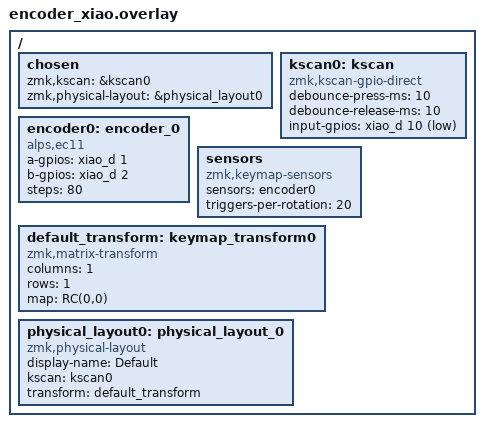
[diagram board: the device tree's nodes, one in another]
#include <dt-bindings/zmk/matrix_transform.h>

/ {
    chosen {
        zmk,kscan = &kscan0;
        zmk,physical-layout = &physical_layout0;
    };

    /*
     * main-board PH 3-pin (B3B-PH) <-> encoder-board:
     *   A = XIAO D1
     *   B = XIAO D2
     *   C = GND
     *
     * ZMK still expects a kscan node; D10 is unused here and kept
     * pulled-up so it never registers a key press.
     */
    kscan0: kscan {
        compatible = "zmk,kscan-gpio-direct";
        debounce-press-ms = <10>;
        debounce-release-ms = <10>;
        input-gpios = <&xiao_d 10 (GPIO_ACTIVE_LOW | GPIO_PULL_UP)>;
    };

    encoder0: encoder_0 {
        compatible = "alps,ec11";
        a-gpios = <&xiao_d 1 (GPIO_ACTIVE_HIGH | GPIO_PULL_UP)>;
        b-gpios = <&xiao_d 2 (GPIO_ACTIVE_HIGH | GPIO_PULL_UP)>;
        steps = <80>;
        status = "okay";
    };

    sensors {
        compatible = "zmk,keymap-sensors";
        sensors = <&encoder0>;
        triggers-per-rotation = <20>;
    };

    default_transform: keymap_transform0 {
        compatible = "zmk,matrix-transform";
        columns = <1>;
        rows = <1>;
        map = <
            RC(0,0)
        >;
    };

    physical_layout0: physical_layout_0 {
        compatible = "zmk,physical-layout";
        display-name = "Default";
        kscan = <&kscan0>;
        transform = <&default_transform>;
    };
};
